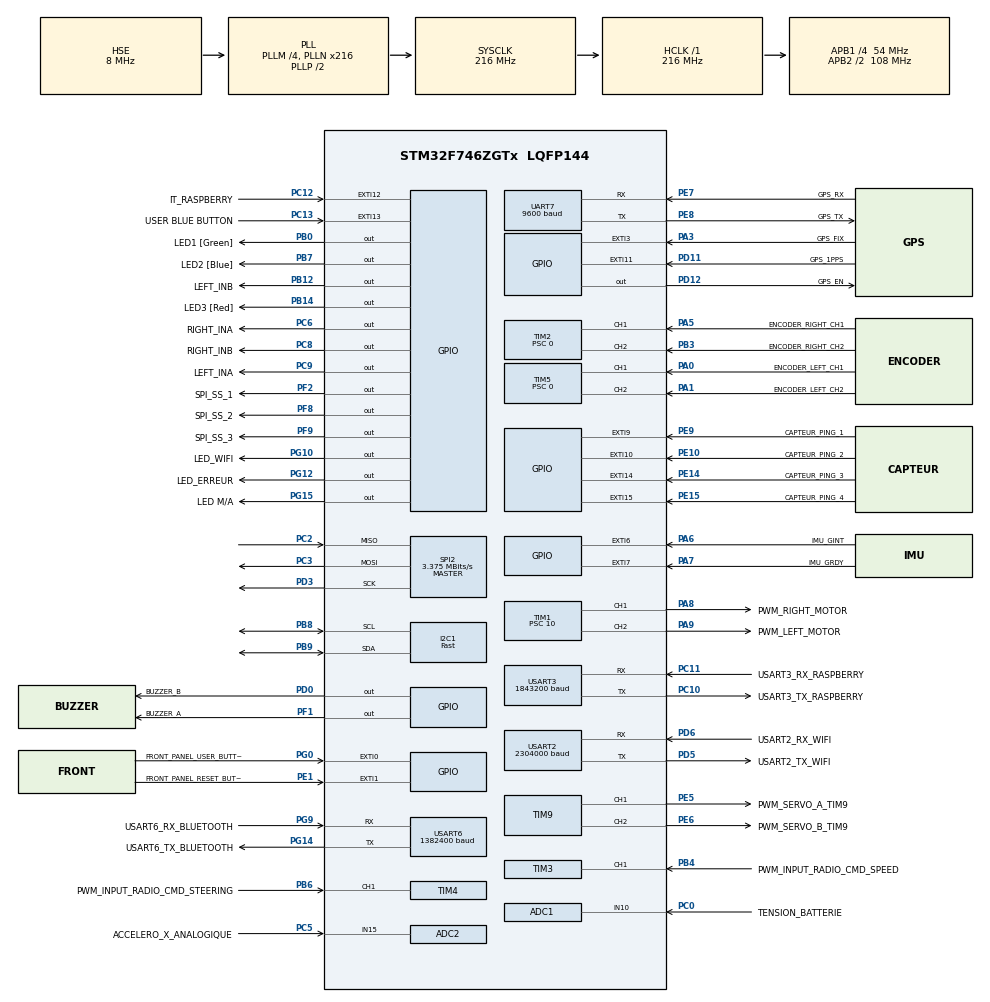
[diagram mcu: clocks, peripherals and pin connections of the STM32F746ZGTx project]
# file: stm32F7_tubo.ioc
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ADC1.Channel-4\#ChannelRegularConversion=ADC_CHANNEL_10
ADC1.ClockPrescaler=ADC_CLOCK_SYNC_PCLK_DIV4
ADC1.ContinuousConvMode=ENABLE
ADC1.DMAContinuousRequests=ENABLE
ADC1.DataAlign=ADC_DATAALIGN_RIGHT
ADC1.DiscontinuousConvMode=DISABLE
ADC1.EOCSelection=ADC_EOC_SEQ_CONV
ADC1.EnableAnalogWatchDog=false
ADC1.ExternalTrigConv=ADC_SOFTWARE_START
ADC1.ExternalTrigConvEdge=ADC_EXTERNALTRIGCONVEDGE_NONE
ADC1.InjNumberOfConversion=0
ADC1.NbrOfConversion=1
ADC1.NbrOfConversionFlag=1
ADC1.Rank-4\#ChannelRegularConversion=1
ADC1.Resolution=ADC_RESOLUTION_12B
ADC1.SamplingTime-4\#ChannelRegularConversion=ADC_SAMPLETIME_144CYCLES
ADC1.ScanConvMode=DISABLE
ADC1.master=1
ADC2.Channel-0\#ChannelRegularConversion=ADC_CHANNEL_15
ADC2.ClockPrescaler=ADC_CLOCK_SYNC_PCLK_DIV4
ADC2.ContinuousConvMode=ENABLE
ADC2.DMAContinuousRequests=ENABLE
ADC2.DataAlign=ADC_DATAALIGN_RIGHT
ADC2.DiscontinuousConvMode=DISABLE
ADC2.EOCSelection=ADC_EOC_SEQ_CONV
ADC2.EnableAnalogWatchDog=false
ADC2.ExternalTrigConv=ADC_SOFTWARE_START
ADC2.ExternalTrigConvEdge=ADC_EXTERNALTRIGCONVEDGE_NONE
ADC2.InjNumberOfConversion=0
ADC2.NbrOfConversion=1
ADC2.NbrOfConversionFlag=1
ADC2.Rank-0\#ChannelRegularConversion=1
ADC2.Resolution=ADC_RESOLUTION_12B
ADC2.SamplingTime-0\#ChannelRegularConversion=ADC_SAMPLETIME_480CYCLES
ADC2.ScanConvMode=DISABLE
CORTEX_M7.ART_ACCLERATOR_ENABLE=1
CORTEX_M7.CPU_DCache=Enabled
CORTEX_M7.CPU_ICache=Enabled
CORTEX_M7.Enable-Cortex_Memory_Protection_Unit_Region0_Settings=MPU_REGION_ENABLE
CORTEX_M7.MPU_Control=__NULL
CORTEX_M7.PREFETCH_ENABLE=1
CORTEX_M7.SubRegionDisable-Cortex_Memory_Protection_Unit_Region0_Settings=0x0
Dma.ADC1.7.Direction=DMA_PERIPH_TO_MEMORY
Dma.ADC1.7.FIFOMode=DMA_FIFOMODE_DISABLE
Dma.ADC1.7.Instance=DMA2_Stream0
Dma.ADC1.7.MemDataAlignment=DMA_MDATAALIGN_HALFWORD
Dma.ADC1.7.MemInc=DMA_MINC_ENABLE
Dma.ADC1.7.Mode=DMA_CIRCULAR
Dma.ADC1.7.PeriphDataAlignment=DMA_PDATAALIGN_HALFWORD
Dma.ADC1.7.PeriphInc=DMA_PINC_DISABLE
Dma.ADC1.7.Priority=DMA_PRIORITY_MEDIUM
Dma.ADC2.6.Direction=DMA_PERIPH_TO_MEMORY
Dma.ADC2.6.FIFOMode=DMA_FIFOMODE_DISABLE
Dma.ADC2.6.Instance=DMA2_Stream2
Dma.ADC2.6.MemDataAlignment=DMA_MDATAALIGN_HALFWORD
Dma.ADC2.6.MemInc=DMA_MINC_ENABLE
Dma.ADC2.6.Mode=DMA_CIRCULAR
Dma.ADC2.6.PeriphDataAlignment=DMA_PDATAALIGN_HALFWORD
Dma.ADC2.6.PeriphInc=DMA_PINC_DISABLE
Dma.ADC2.6.Priority=DMA_PRIORITY_HIGH
Dma.Request0=USART2_TX
Dma.Request1=USART2_RX
Dma.Request2=USART3_RX
Dma.Request3=USART3_TX
Dma.Request4=USART6_RX
Dma.Request5=USART6_TX
Dma.Request6=ADC2
Dma.Request7=ADC1
Dma.USART2_RX.1.Direction=DMA_PERIPH_TO_MEMORY
Dma.USART2_RX.1.FIFOMode=DMA_FIFOMODE_DISABLE
Dma.USART2_RX.1.Instance=DMA1_Stream5
Dma.USART2_RX.1.MemDataAlignment=DMA_MDATAALIGN_BYTE
Dma.USART2_RX.1.MemInc=DMA_MINC_ENABLE
Dma.USART2_RX.1.Mode=DMA_CIRCULAR
Dma.USART2_RX.1.PeriphDataAlignment=DMA_PDATAALIGN_BYTE
Dma.USART2_RX.1.PeriphInc=DMA_PINC_DISABLE
Dma.USART2_RX.1.Priority=DMA_PRIORITY_HIGH
Dma.USART2_TX.0.Direction=DMA_MEMORY_TO_PERIPH
Dma.USART2_TX.0.FIFOMode=DMA_FIFOMODE_ENABLE
Dma.USART2_TX.0.FIFOThreshold=DMA_FIFO_THRESHOLD_FULL
Dma.USART2_TX.0.Instance=DMA1_Stream6
Dma.USART2_TX.0.MemBurst=DMA_MBURST_SINGLE
Dma.USART2_TX.0.MemDataAlignment=DMA_MDATAALIGN_BYTE
Dma.USART2_TX.0.MemInc=DMA_MINC_ENABLE
Dma.USART2_TX.0.Mode=DMA_NORMAL
Dma.USART2_TX.0.PeriphBurst=DMA_PBURST_SINGLE
Dma.USART2_TX.0.PeriphDataAlignment=DMA_PDATAALIGN_BYTE
Dma.USART2_TX.0.PeriphInc=DMA_PINC_DISABLE
Dma.USART2_TX.0.Priority=DMA_PRIORITY_VERY_HIGH
Dma.USART3_RX.2.Direction=DMA_PERIPH_TO_MEMORY
Dma.USART3_RX.2.FIFOMode=DMA_FIFOMODE_DISABLE
Dma.USART3_RX.2.Instance=DMA1_Stream1
Dma.USART3_RX.2.MemDataAlignment=DMA_MDATAALIGN_BYTE
Dma.USART3_RX.2.MemInc=DMA_MINC_ENABLE
Dma.USART3_RX.2.Mode=DMA_CIRCULAR
Dma.USART3_RX.2.PeriphDataAlignment=DMA_PDATAALIGN_BYTE
Dma.USART3_RX.2.PeriphInc=DMA_PINC_DISABLE
Dma.USART3_RX.2.Priority=DMA_PRIORITY_HIGH
Dma.USART3_TX.3.Direction=DMA_MEMORY_TO_PERIPH
Dma.USART3_TX.3.FIFOMode=DMA_FIFOMODE_DISABLE
Dma.USART3_TX.3.Instance=DMA1_Stream3
Dma.USART3_TX.3.MemDataAlignment=DMA_MDATAALIGN_BYTE
Dma.USART3_TX.3.MemInc=DMA_MINC_ENABLE
Dma.USART3_TX.3.Mode=DMA_NORMAL
Dma.USART3_TX.3.PeriphDataAlignment=DMA_PDATAALIGN_BYTE
Dma.USART3_TX.3.PeriphInc=DMA_PINC_DISABLE
Dma.USART3_TX.3.Priority=DMA_PRIORITY_VERY_HIGH
Dma.USART6_RX.4.Direction=DMA_PERIPH_TO_MEMORY
Dma.USART6_RX.4.FIFOMode=DMA_FIFOMODE_DISABLE
Dma.USART6_RX.4.Instance=DMA2_Stream1
Dma.USART6_RX.4.MemDataAlignment=DMA_MDATAALIGN_BYTE
Dma.USART6_RX.4.MemInc=DMA_MINC_ENABLE
Dma.USART6_RX.4.Mode=DMA_CIRCULAR
Dma.USART6_RX.4.PeriphDataAlignment=DMA_PDATAALIGN_BYTE
Dma.USART6_RX.4.PeriphInc=DMA_PINC_DISABLE
Dma.USART6_RX.4.Priority=DMA_PRIORITY_VERY_HIGH
Dma.USART6_TX.5.Direction=DMA_MEMORY_TO_PERIPH
Dma.USART6_TX.5.FIFOMode=DMA_FIFOMODE_ENABLE
Dma.USART6_TX.5.FIFOThreshold=DMA_FIFO_THRESHOLD_FULL
Dma.USART6_TX.5.Instance=DMA2_Stream6
Dma.USART6_TX.5.MemBurst=DMA_MBURST_SINGLE
Dma.USART6_TX.5.MemDataAlignment=DMA_MDATAALIGN_BYTE
Dma.USART6_TX.5.MemInc=DMA_MINC_ENABLE
Dma.USART6_TX.5.Mode=DMA_NORMAL
Dma.USART6_TX.5.PeriphBurst=DMA_PBURST_SINGLE
Dma.USART6_TX.5.PeriphDataAlignment=DMA_PDATAALIGN_BYTE
Dma.USART6_TX.5.PeriphInc=DMA_PINC_DISABLE
Dma.USART6_TX.5.Priority=DMA_PRIORITY_HIGH
I2C1.Analog_Filter=I2C_ANALOGFILTER_ENABLE
I2C1.I2C_Speed_Mode=I2C_Fast
I2C1.Timing=0x6000030D
Mcu.Family=STM32F7
Mcu.Name=STM32F746ZGTx
Mcu.Package=LQFP144
NVIC.DMA1_Stream1_IRQn=true\:0\:0\:false\:false\:true\:true\:true
NVIC.DMA1_Stream3_IRQn=true\:0\:0\:false\:false\:true\:true\:true
NVIC.DMA1_Stream5_IRQn=true\:0\:0\:false\:false\:true\:true\:true
NVIC.DMA1_Stream6_IRQn=true\:0\:0\:false\:false\:true\:true\:true
NVIC.DMA2_Stream0_IRQn=true\:0\:0\:false\:false\:true\:true\:true
NVIC.DMA2_Stream1_IRQn=true\:0\:0\:false\:false\:true\:true\:true
NVIC.DMA2_Stream2_IRQn=true\:0\:0\:false\:false\:true\:true\:true
NVIC.DMA2_Stream6_IRQn=true\:0\:0\:false\:false\:true\:true\:true
NVIC.EXTI0_IRQn=true\:0\:0\:false\:false\:true\:true\:true
NVIC.EXTI15_10_IRQn=true\:2\:0\:true\:false\:true\:true\:true
NVIC.EXTI1_IRQn=true\:0\:0\:false\:false\:true\:true\:true
NVIC.EXTI9_5_IRQn=true\:2\:0\:true\:false\:true\:true\:true
NVIC.PriorityGroup=NVIC_PRIORITYGROUP_4
NVIC.TIM8_UP_TIM13_IRQn=true\:1\:0\:true\:false\:true\:true\:true
NVIC.UART7_IRQn=true\:5\:0\:true\:false\:true\:true\:true
NVIC.USART2_IRQn=true\:6\:0\:true\:false\:true\:true\:true
NVIC.USART3_IRQn=true\:7\:0\:true\:false\:true\:true\:true
NVIC.USART6_IRQn=true\:8\:0\:true\:false\:true\:true\:true
PA0/WKUP.GPIO_Label=ENCODER_LEFT_CH1
PA0/WKUP.Signal=S_TIM5_CH1
PA1.GPIO_Label=ENCODER_LEFT_CH2
PA1.Signal=S_TIM5_CH2
PA13.GPIO_Label=TMS
PA13.Mode=Serial_Wire
PA13.Signal=SYS_JTMS-SWDIO
PA14.GPIO_Label=TCK
PA14.Mode=Serial_Wire
PA14.Signal=SYS_JTCK-SWCLK
PA3.GPIO_Label=GPS_FIX
PA3.Signal=GPXTI3
PA5.GPIO_Label=ENCODER_RIGHT_CH1
PA5.GPIO_ModeDefaultPP=GPIO_MODE_AF_PP
PA5.Signal=S_TIM2_CH1_ETR
PA6.GPIO_Label=IMU_GINT
PA6.Signal=GPXTI6
PA7.GPIO_Label=IMU_GRDY
PA7.Signal=GPXTI7
PA8.GPIO_Label=PWM_RIGHT_MOTOR
PA8.GPIO_ModeDefaultPP=GPIO_MODE_AF_PP
PA8.Signal=S_TIM1_CH1
PA9.GPIO_Label=PWM_LEFT_MOTOR
PA9.Signal=S_TIM1_CH2
PB0.GPIO_Label=LED1 [Green]
PB0.GPIO_ModeDefaultOutputPP=GPIO_MODE_OUTPUT_OD
PB0.Signal=GPIO_Output
PB12.GPIO_Label=LEFT_INB
PB12.GPIO_Speed=GPIO_SPEED_FREQ_LOW
PB12.Signal=GPIO_Output
PB14.GPIO_Label=LED3 [Red]
PB14.GPIO_ModeDefaultOutputPP=GPIO_MODE_OUTPUT_OD
PB14.Signal=GPIO_Output
PB3.GPIO_Label=ENCODER_RIGHT_CH2
PB3.Signal=S_TIM2_CH2
PB4.GPIO_Label=PWM_INPUT_RADIO_CMD_SPEED
PB4.Signal=S_TIM3_CH1
PB6.GPIO_Label=PWM_INPUT_RADIO_CMD_STEERING
PB6.Signal=S_TIM4_CH1
PB7.GPIO_Label=LED2 [Blue]
PB7.GPIO_ModeDefaultOutputPP=GPIO_MODE_OUTPUT_OD
PB7.Signal=GPIO_Output
PB8.GPIO_Mode=GPIO_MODE_AF_OD
PB8.GPIO_Speed=GPIO_SPEED_FREQ_VERY_HIGH
PB8.Mode=I2C
PB8.Signal=I2C1_SCL
PB9.GPIO_Mode=GPIO_MODE_AF_OD
PB9.GPIO_PuPdOD=GPIO_PULLUP
PB9.Mode=I2C
PB9.Signal=I2C1_SDA
PC0.GPIO_Label=TENSION_BATTERIE
PC0.Signal=ADCx_IN10
PC10.GPIO_Label=USART3_TX_RASPBERRY
PC10.Mode=Asynchronous
PC10.Signal=USART3_TX
PC11.GPIO_Label=USART3_RX_RASPBERRY
PC11.Mode=Asynchronous
PC11.Signal=USART3_RX
PC12.GPIO_Label=IT_RASPBERRY
PC12.Signal=GPXTI12
PC13.GPIO_Label=USER BLUE BUTTON
PC13.Signal=GPXTI13
PC14/OSC32_IN.Mode=LSE-External-Clock-Source
PC14/OSC32_IN.Signal=RCC_OSC32_IN
PC15/OSC32_OUT.Mode=LSE-External-Clock-Source
PC15/OSC32_OUT.Signal=RCC_OSC32_OUT
PC2.Mode=Full_Duplex_Master
PC2.Signal=SPI2_MISO
PC3.Mode=Full_Duplex_Master
PC3.Signal=SPI2_MOSI
PC5.GPIO_Label=ACCELERO_X_ANALOGIQUE
PC5.Signal=ADCx_IN15
PC6.GPIO_Label=RIGHT_INA
PC6.GPIO_ModeDefaultOutputPP=GPIO_MODE_OUTPUT_PP
PC6.Signal=GPIO_Output
PC8.GPIO_Label=RIGHT_INB
PC8.GPIO_ModeDefaultOutputPP=GPIO_MODE_OUTPUT_PP
PC8.Signal=GPIO_Output
PC9.GPIO_Label=LEFT_INA
PC9.Signal=GPIO_Output
PD0.GPIO_Label=BUZZER_B
PD0.Signal=GPIO_Output
PD11.GPIO_Label=GPS_1PPS
PD11.Signal=GPXTI11
PD12.GPIO_Label=GPS_EN
PD12.Signal=GPIO_Output
PD3.Mode=Full_Duplex_Master
PD3.Signal=SPI2_SCK
PD5.GPIO_Label=USART2_TX_WIFI
PD5.Mode=Asynchronous
PD5.Signal=USART2_TX
PD6.GPIO_Label=USART2_RX_WIFI
PD6.GPIO_Speed=GPIO_SPEED_FREQ_VERY_HIGH
PD6.Mode=Asynchronous
PD6.Signal=USART2_RX
PE1.GPIO_Label=FRONT_PANEL_RESET_BUTTON
PE1.GPIO_PuPd=GPIO_PULLUP
PE1.Signal=GPXTI1
PE10.GPIO_Label=CAPTEUR_PING_2
PE10.Signal=GPXTI10
PE14.GPIO_Label=CAPTEUR_PING_3
PE14.Signal=GPXTI14
PE15.GPIO_Label=CAPTEUR_PING_4
PE15.Signal=GPXTI15
PE5.GPIO_Label=PWM_SERVO_A_TIM9
PE5.Signal=S_TIM9_CH1
PE6.GPIO_Label=PWM_SERVO_B_TIM9
PE6.Signal=S_TIM9_CH2
PE7.GPIO_Label=GPS_RX
PE7.Mode=Asynchronous
PE7.Signal=UART7_RX
PE8.GPIO_Label=GPS_TX
PE8.Mode=Asynchronous
PE8.Signal=UART7_TX
PE9.GPIO_Label=CAPTEUR_PING_1
PE9.Signal=GPXTI9
PF1.GPIO_Label=BUZZER_A
PF1.Signal=GPIO_Output
PF2.GPIO_Label=SPI_SS_1
PF2.Signal=GPIO_Output
PF8.GPIO_Label=SPI_SS_2
PF8.Signal=GPIO_Output
PF9.GPIO_Label=SPI_SS_3
PF9.Signal=GPIO_Output
PG0.GPIO_Label=FRONT_PANEL_USER_BUTTON
PG0.GPIO_ModeDefaultEXTI=GPIO_MODE_IT_RISING
PG0.GPIO_PuPd=GPIO_PULLUP
PG0.Signal=GPXTI0
PG10.GPIO_Label=LED_WIFI
PG10.GPIO_ModeDefaultOutputPP=GPIO_MODE_OUTPUT_OD
PG10.PinState=GPIO_PIN_RESET
PG10.Signal=GPIO_Output
PG12.GPIO_Label=LED_ERREUR
PG12.GPIO_ModeDefaultOutputPP=GPIO_MODE_OUTPUT_OD
PG12.Signal=GPIO_Output
PG14.GPIO_Label=USART6_TX_BLUETOOTH
PG14.GPIO_Mode=GPIO_MODE_AF_PP
PG14.GPIO_PuPd=GPIO_PULLUP
PG14.Mode=Asynchronous
PG14.Signal=USART6_TX
PG15.GPIO_Label=LED M/A
PG15.GPIO_ModeDefaultOutputPP=GPIO_MODE_OUTPUT_OD
PG15.Signal=GPIO_Output
PG9.GPIO_Label=USART6_RX_BLUETOOTH
PG9.Mode=Asynchronous
PG9.Signal=USART6_RX
PH0/OSC_IN.GPIO_Label=MCO [STM32F103CBT6_PA8]
PH0/OSC_IN.Mode=HSE-External-Clock-Source
PH0/OSC_IN.Signal=RCC_OSC_IN
PH1/OSC_OUT.Mode=HSE-External-Clock-Source
PH1/OSC_OUT.Signal=RCC_OSC_OUT
ProjectManager.HeapSize=0x4000
ProjectManager.StackSize=0x1000
ProjectManager.TargetToolchain=SW4STM32
RCC.48MHZClocksFreq_Value=24000000
RCC.AHBFreq_Value=216000000
RCC.APB1CLKDivider=RCC_HCLK_DIV4
RCC.APB1Freq_Value=54000000
RCC.APB1TimFreq_Value=108000000
RCC.APB2CLKDivider=RCC_HCLK_DIV2
RCC.APB2Freq_Value=108000000
RCC.APB2TimFreq_Value=216000000
RCC.CortexFreq_Value=216000000
RCC.HCLKFreq_Value=216000000
RCC.HSE_VALUE=8000000
RCC.HSI_VALUE=16000000
RCC.LSE_VALUE=0.00000000000000000000000000000000000000000000000000000000000000000000000000000000000000000032767
RCC.PLLM=4
RCC.PLLMUL=RCC_PLL_MUL9
RCC.PLLN=216
RCC.PLLQ=9
RCC.PLLSourceVirtual=RCC_PLLSOURCE_HSE
RCC.PRESCALERUSB=RCC_USBCLKSOURCE_PLL_DIV1_5
RCC.SYSCLKFreq_VALUE=216000000
RCC.SYSCLKSource=RCC_SYSCLKSOURCE_PLLCLK
RCC.SYSCLKSourceVirtual=RCC_SYSCLKSOURCE_PLLCLK
RCC.USBFreq_Value=48000000
RCC.VCOOutputFreq_Value=432000000
SH.ADCx_IN10.0=ADC1_IN10,IN10
SH.ADCx_IN15.0=ADC2_IN15,IN15
SH.S_TIM1_CH1.0=TIM1_CH1,PWM Generation1 CH1
SH.S_TIM1_CH2.0=TIM1_CH2,PWM Generation2 CH2
SH.S_TIM2_CH1_ETR.0=TIM2_CH1,Encoder_Interface
SH.S_TIM2_CH2.0=TIM2_CH2,Encoder_Interface
SH.S_TIM3_CH1.0=TIM3_CH1,PWM_Input_1
SH.S_TIM4_CH1.0=TIM4_CH1,PWM_Input_1
SH.S_TIM5_CH1.0=TIM5_CH1,Encoder_Interface
SH.S_TIM5_CH2.0=TIM5_CH2,Encoder_Interface
SH.S_TIM9_CH1.0=TIM9_CH1,PWM Generation1 CH1
SH.S_TIM9_CH2.0=TIM9_CH2,PWM Generation2 CH2
SPI2.BaudRatePrescaler=SPI_BAUDRATEPRESCALER_16
SPI2.CLKPhase=SPI_PHASE_2EDGE
SPI2.CLKPolarity=SPI_POLARITY_HIGH
SPI2.CalculateBaudRate=3.375 MBits/s
SPI2.Direction=SPI_DIRECTION_2LINES
SPI2.Mode=SPI_MODE_MASTER
SPI2.VirtualType=VM_MASTER
TIM1.Channel-PWM\ Generation1\ CH1=TIM_CHANNEL_1
TIM1.Channel-PWM\ Generation2\ CH2=TIM_CHANNEL_2
TIM1.OCMode_PWM-PWM\ Generation2\ CH2=TIM_OCMODE_PWM1
TIM1.OCPolarity_1=TIM_OCPOLARITY_HIGH
TIM1.Period=999
TIM1.Prescaler=10
TIM13.ClockDivision=TIM_CLOCKDIVISION_DIV1
TIM13.Period=24
TIM13.Prescaler=10799
TIM14.Period=49
TIM14.Prescaler=10799
TIM2.EncoderMode=TIM_ENCODERMODE_TI12
TIM2.IC1Filter=0
TIM2.IC2Filter=0
TIM2.Period=0xFFFFFFFF
TIM2.Prescaler=0
TIM3.Period=0xFFFF
TIM3.Prescaler=107
TIM4.ClockDivision=TIM_CLOCKDIVISION_DIV4
TIM4.ICPolarity_1=TIM_INPUTCHANNELPOLARITY_RISING
TIM4.Period=0xffff
TIM4.Prescaler=0
TIM5.EncoderMode=TIM_ENCODERMODE_TI12
TIM5.IC1Filter=0
TIM5.IC1Polarity=TIM_ICPOLARITY_RISING
TIM5.IC2Filter=0
TIM5.IC2Polarity=TIM_ICPOLARITY_FALLING
TIM5.Period=0xFFFFFFFF
TIM5.Prescaler=0
TIM6.Period=9
TIM6.Prescaler=10799
TIM7.Period=9999
TIM7.Prescaler=10799
TIM9.Channel-PWM\ Generation1\ CH1=TIM_CHANNEL_1
TIM9.Channel-PWM\ Generation2\ CH2=TIM_CHANNEL_2
UART7.BaudRate=9600
UART7.WordLength=WORDLENGTH_8B
USART2.BaudRate=2304000
USART2.VirtualMode-Asynchronous=VM_ASYNC
USART2.WordLength=WORDLENGTH_8B
USART3.BaudRate=1843200
USART3.VirtualMode-Asynchronous=VM_ASYNC
USART3.WordLength=WORDLENGTH_8B
USART6.BaudRate=1382400
USART6.VirtualMode-Asynchronous=VM_ASYNC
USART6.WordLength=WORDLENGTH_8B
VP_TIM13_VS_ClockSourceINT.Mode=Enable_Timer
VP_TIM14_VS_ClockSourceINT.Mode=Enable_Timer
VP_TIM6_VS_ClockSourceINT.Mode=Enable_Timer
VP_TIM7_VS_ClockSourceINT.Mode=Enable_Timer
board=NUCLEO-F746ZG

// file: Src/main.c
/* USER CODE BEGIN Header */
/**
  ******************************************************************************
  * @file           : main.c
  * @brief          : Main program body
  ******************************************************************************
  * @attention
  *
  * <h2><center>&copy; Copyright (c) 2019 STMicroelectronics.
  * All rights reserved.</center></h2>
  *
  * This software component is licensed by ST under BSD 3-Clause license,
  * the "License"; You may not use this file except in compliance with the
  * License. You may obtain a copy of the License at:
  *                        opensource.org/licenses/BSD-3-Clause
  *
  ******************************************************************************
  */
/* USER CODE END Header */

#include "main.h"
#include "adc.h"
#include "dma.h"
#include "gfxsimulator.h"
#include "i2c.h"
#include "spi.h"
#include "tim.h"
#include "usart.h"
#include "gpio.h"

/* USER CODE BEGIN Includes */

#include "stm32f7xx_nucleo_144.h"
#include "utils.h"

extern void mainSetup ( void ) ;
extern void mainLoop  ( void ) ;

/* USER CODE END Includes */

void SystemClock_Config(void);

int main(void)
{

  /* Enable I-Cache---------------------------------------------------------*/
  SCB_EnableICache();

  /* Enable D-Cache---------------------------------------------------------*/
  SCB_EnableDCache();

  /* MCU Configuration--------------------------------------------------------*/

  /* Reset of all peripherals, Initializes the Flash interface and the Systick. */
  HAL_Init();

  /* Configure the system clock */
  SystemClock_Config();

  /* Initialize all configured peripherals */
  MX_GPIO_Init();
  MX_DMA_Init();
  MX_USART2_UART_Init();
  MX_USART3_UART_Init();
  MX_USART6_UART_Init();
  MX_UART7_Init();
  MX_I2C1_Init();
  MX_TIM1_Init();
  MX_TIM2_Init();
  MX_TIM3_Init();
  MX_TIM4_Init();
  MX_TIM5_Init();
  MX_TIM6_Init();
  MX_TIM9_Init();
  MX_TIM7_Init();
  MX_TIM13_Init();
  MX_TIM14_Init();
  MX_ADC1_Init();
  MX_ADC2_Init();
  MX_SPI2_Init();
  MX_GFXSIMULATOR_Init();
  /* USER CODE BEGIN 2 */

	BSP_LED_Init ( LED_GREEN ) ;
	BSP_LED_Init ( LED_BLUE  ) ;
	BSP_LED_Init ( LED_RED 	 ) ;

	BSP_LED_On ( LED_BLUE  ) ;
	BSP_LED_On ( LED_GREEN ) ;
	BSP_LED_On ( LED_RED   ) ;

	mainSetup () ;
  /* USER CODE END 2 */

  /* Infinite loop */
  /* USER CODE BEGIN WHILE */
  while (1)
  {
	mainLoop () ;

    /* USER CODE END WHILE */

  }
}

void SystemClock_Config(void)
{
  RCC_OscInitTypeDef RCC_OscInitStruct = {0};
  RCC_ClkInitTypeDef RCC_ClkInitStruct = {0};
  RCC_PeriphCLKInitTypeDef PeriphClkInitStruct = {0};

  /** Configure the main internal regulator output voltage
  */
  __HAL_RCC_PWR_CLK_ENABLE();
  __HAL_PWR_VOLTAGESCALING_CONFIG(PWR_REGULATOR_VOLTAGE_SCALE1);
  /** Initializes the CPU, AHB and APB busses clocks
  */
  RCC_OscInitStruct.OscillatorType = RCC_OSCILLATORTYPE_HSE;
  RCC_OscInitStruct.HSEState = RCC_HSE_BYPASS;
  RCC_OscInitStruct.PLL.PLLState = RCC_PLL_ON;
  RCC_OscInitStruct.PLL.PLLSource = RCC_PLLSOURCE_HSE;
  RCC_OscInitStruct.PLL.PLLM = 4;
  RCC_OscInitStruct.PLL.PLLN = 216;
  RCC_OscInitStruct.PLL.PLLP = RCC_PLLP_DIV2;
  RCC_OscInitStruct.PLL.PLLQ = 9;
  if (HAL_RCC_OscConfig(&RCC_OscInitStruct) != HAL_OK)
  {
    Error_Handler();
  }
  /** Activate the Over-Drive mode
  */
  if (HAL_PWREx_EnableOverDrive() != HAL_OK)
  {
    Error_Handler();
  }
  /** Initializes the CPU, AHB and APB busses clocks
  */
  RCC_ClkInitStruct.ClockType = RCC_CLOCKTYPE_HCLK|RCC_CLOCKTYPE_SYSCLK
                              |RCC_CLOCKTYPE_PCLK1|RCC_CLOCKTYPE_PCLK2;
  RCC_ClkInitStruct.SYSCLKSource = RCC_SYSCLKSOURCE_PLLCLK;
  RCC_ClkInitStruct.AHBCLKDivider = RCC_SYSCLK_DIV1;
  RCC_ClkInitStruct.APB1CLKDivider = RCC_HCLK_DIV4;
  RCC_ClkInitStruct.APB2CLKDivider = RCC_HCLK_DIV2;

  if (HAL_RCC_ClockConfig(&RCC_ClkInitStruct, FLASH_LATENCY_7) != HAL_OK)
  {
    Error_Handler();
  }
  PeriphClkInitStruct.PeriphClockSelection = RCC_PERIPHCLK_USART2|RCC_PERIPHCLK_USART3
                              |RCC_PERIPHCLK_USART6|RCC_PERIPHCLK_UART7
                              |RCC_PERIPHCLK_I2C1;
  PeriphClkInitStruct.Usart2ClockSelection = RCC_USART2CLKSOURCE_PCLK1;
  PeriphClkInitStruct.Usart3ClockSelection = RCC_USART3CLKSOURCE_PCLK1;
  PeriphClkInitStruct.Usart6ClockSelection = RCC_USART6CLKSOURCE_PCLK2;
  PeriphClkInitStruct.Uart7ClockSelection = RCC_UART7CLKSOURCE_PCLK1;
  PeriphClkInitStruct.I2c1ClockSelection = RCC_I2C1CLKSOURCE_PCLK1;
  if (HAL_RCCEx_PeriphCLKConfig(&PeriphClkInitStruct) != HAL_OK)
  {
    Error_Handler();
  }
}

void Error_Handler(void)
{
}

/************************ (C) COPYRIGHT STMicroelectronics *****END OF FILE****/
